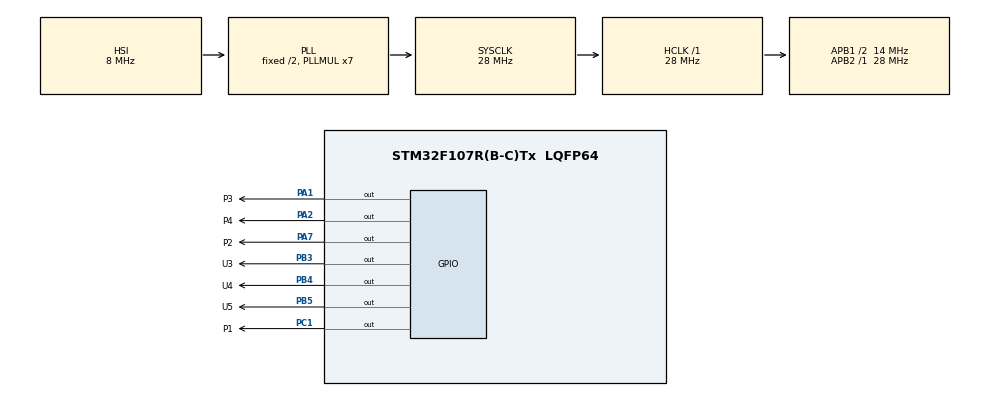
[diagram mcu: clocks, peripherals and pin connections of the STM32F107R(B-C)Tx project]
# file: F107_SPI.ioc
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Mcu.Family=STM32F1
Mcu.Name=STM32F107R(B-C)Tx
Mcu.Package=LQFP64
NVIC.PriorityGroup=NVIC_PRIORITYGROUP_4
PA1.GPIO_Label=P3
PA1.GPIO_Speed=GPIO_SPEED_FREQ_HIGH
PA1.Signal=GPIO_Output
PA13.Mode=Serial_Wire
PA13.Signal=SYS_JTMS-SWDIO
PA14.Mode=Serial_Wire
PA14.Signal=SYS_JTCK-SWCLK
PA2.GPIO_Label=P4
PA2.GPIO_Speed=GPIO_SPEED_FREQ_HIGH
PA2.Signal=GPIO_Output
PA7.GPIO_Label=P2
PA7.GPIO_Speed=GPIO_SPEED_FREQ_HIGH
PA7.Signal=GPIO_Output
PB3.GPIO_Label=U3
PB3.GPIO_ModeDefaultOutputPP=GPIO_MODE_OUTPUT_PP
PB3.GPIO_PuPd=GPIO_NOPULL
PB3.GPIO_Speed=GPIO_SPEED_FREQ_HIGH
PB3.PinState=GPIO_PIN_RESET
PB3.Signal=GPIO_Output
PB4.GPIO_Label=U4
PB4.GPIO_Speed=GPIO_SPEED_FREQ_HIGH
PB4.Signal=GPIO_Output
PB5.GPIO_Label=U5
PB5.GPIO_Speed=GPIO_SPEED_FREQ_HIGH
PB5.Signal=GPIO_Output
PC1.GPIO_Label=P1
PC1.GPIO_Speed=GPIO_SPEED_FREQ_HIGH
PC1.Signal=GPIO_Output
ProjectManager.HeapSize=0x200
ProjectManager.StackSize=0x400
ProjectManager.TargetToolchain=STM32CubeIDE
RCC.AHBFreq_Value=28000000
RCC.APB1CLKDivider=RCC_HCLK_DIV2
RCC.APB1Freq_Value=14000000
RCC.APB1TimFreq_Value=28000000
RCC.APB2Freq_Value=28000000
RCC.APB2TimFreq_Value=28000000
RCC.HCLKFreq_Value=28000000
RCC.HSE_VALUE=10000000
RCC.PLLMUL=RCC_PLL_MUL7
RCC.SYSCLKFreq_VALUE=28000000
RCC.SYSCLKSource=RCC_SYSCLKSOURCE_PLLCLK
RCC.USBFreq_Value=18666666.666666668
board=custom

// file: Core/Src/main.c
/* USER CODE BEGIN Header */
/**
  ******************************************************************************
  * @file           : main.c
  * @brief          : Main program body
  ******************************************************************************
  * @attention
  *
  * Copyright (c) 2022 STMicroelectronics.
  * All rights reserved.
  *
  * This software is licensed under terms that can be found in the LICENSE file
  * in the root directory of this software component.
  * If no LICENSE file comes with this software, it is provided AS-IS.
  *
  ******************************************************************************
  */
/* USER CODE END Header */
#include "main.h"

void SystemClock_Config(void);
static void MX_GPIO_Init(void);

int main(void)
{

  /* MCU Configuration--------------------------------------------------------*/

  /* Reset of all peripherals, Initializes the Flash interface and the Systick. */
  HAL_Init();

  /* Configure the system clock */
  SystemClock_Config();

  /* Initialize all configured peripherals */
  MX_GPIO_Init();

  /* Infinite loop */
  /* USER CODE BEGIN WHILE */
  while (1)
  {
		  HAL_Delay(1000);
		  HAL_GPIO_WritePin(GPIOA, P3_Pin|P4_Pin|P2_Pin, GPIO_PIN_RESET);
		  HAL_GPIO_WritePin(P1_GPIO_Port, P1_Pin, GPIO_PIN_RESET);
		  HAL_GPIO_WritePin(GPIOB, U3_Pin|U4_Pin|U5_Pin, GPIO_PIN_RESET);
		  HAL_Delay(1000);
		  HAL_GPIO_WritePin(GPIOA, P3_Pin|P4_Pin|P2_Pin, GPIO_PIN_SET);
		  HAL_GPIO_WritePin(P1_GPIO_Port, P1_Pin, GPIO_PIN_SET);
		  HAL_GPIO_WritePin(GPIOB, U3_Pin|U4_Pin|U5_Pin, GPIO_PIN_SET);
    /* USER CODE END WHILE */

  }
}

void SystemClock_Config(void)
{
  RCC_OscInitTypeDef RCC_OscInitStruct = {0};
  RCC_ClkInitTypeDef RCC_ClkInitStruct = {0};

  /** Initializes the RCC Oscillators according to the specified parameters
  * in the RCC_OscInitTypeDef structure.
  */
  RCC_OscInitStruct.OscillatorType = RCC_OSCILLATORTYPE_HSI;
  RCC_OscInitStruct.HSIState = RCC_HSI_ON;
  RCC_OscInitStruct.HSICalibrationValue = RCC_HSICALIBRATION_DEFAULT;
  RCC_OscInitStruct.Prediv1Source = RCC_PREDIV1_SOURCE_HSE;
  RCC_OscInitStruct.PLL.PLLState = RCC_PLL_ON;
  RCC_OscInitStruct.PLL.PLLSource = RCC_PLLSOURCE_HSI_DIV2;
  RCC_OscInitStruct.PLL.PLLMUL = RCC_PLL_MUL7;
  RCC_OscInitStruct.PLL2.PLL2State = RCC_PLL_NONE;
  if (HAL_RCC_OscConfig(&RCC_OscInitStruct) != HAL_OK)
  {
    Error_Handler();
  }

  /** Initializes the CPU, AHB and APB buses clocks
  */
  RCC_ClkInitStruct.ClockType = RCC_CLOCKTYPE_HCLK|RCC_CLOCKTYPE_SYSCLK
                              |RCC_CLOCKTYPE_PCLK1|RCC_CLOCKTYPE_PCLK2;
  RCC_ClkInitStruct.SYSCLKSource = RCC_SYSCLKSOURCE_PLLCLK;
  RCC_ClkInitStruct.AHBCLKDivider = RCC_SYSCLK_DIV1;
  RCC_ClkInitStruct.APB1CLKDivider = RCC_HCLK_DIV2;
  RCC_ClkInitStruct.APB2CLKDivider = RCC_HCLK_DIV1;

  if (HAL_RCC_ClockConfig(&RCC_ClkInitStruct, FLASH_LATENCY_1) != HAL_OK)
  {
    Error_Handler();
  }

  /** Configure the Systick interrupt time
  */
  __HAL_RCC_PLLI2S_ENABLE();
}

static void MX_GPIO_Init(void)
{
  GPIO_InitTypeDef GPIO_InitStruct = {0};

  /* GPIO Ports Clock Enable */
  __HAL_RCC_GPIOC_CLK_ENABLE();
  __HAL_RCC_GPIOA_CLK_ENABLE();
  __HAL_RCC_GPIOB_CLK_ENABLE();

  /*Configure GPIO pin Output Level */
  HAL_GPIO_WritePin(P1_GPIO_Port, P1_Pin, GPIO_PIN_RESET);

  /*Configure GPIO pin Output Level */
  HAL_GPIO_WritePin(GPIOA, P3_Pin|P4_Pin|P2_Pin, GPIO_PIN_RESET);

  /*Configure GPIO pin Output Level */
  HAL_GPIO_WritePin(GPIOB, U3_Pin|U4_Pin|U5_Pin, GPIO_PIN_RESET);

  /*Configure GPIO pin : P1_Pin */
  GPIO_InitStruct.Pin = P1_Pin;
  GPIO_InitStruct.Mode = GPIO_MODE_OUTPUT_PP;
  GPIO_InitStruct.Pull = GPIO_NOPULL;
  GPIO_InitStruct.Speed = GPIO_SPEED_FREQ_HIGH;
  HAL_GPIO_Init(P1_GPIO_Port, &GPIO_InitStruct);

  /*Configure GPIO pins : P3_Pin P4_Pin P2_Pin */
  GPIO_InitStruct.Pin = P3_Pin|P4_Pin|P2_Pin;
  GPIO_InitStruct.Mode = GPIO_MODE_OUTPUT_PP;
  GPIO_InitStruct.Pull = GPIO_NOPULL;
  GPIO_InitStruct.Speed = GPIO_SPEED_FREQ_HIGH;
  HAL_GPIO_Init(GPIOA, &GPIO_InitStruct);

  /*Configure GPIO pins : U3_Pin U4_Pin U5_Pin */
  GPIO_InitStruct.Pin = U3_Pin|U4_Pin|U5_Pin;
  GPIO_InitStruct.Mode = GPIO_MODE_OUTPUT_PP;
  GPIO_InitStruct.Pull = GPIO_NOPULL;
  GPIO_InitStruct.Speed = GPIO_SPEED_FREQ_HIGH;
  HAL_GPIO_Init(GPIOB, &GPIO_InitStruct);

}

void Error_Handler(void)
{
  __disable_irq();
  while (1)
  {
  }
}
